# MK81F25615 register map
Vendor: Freescale Semiconductor, Inc.; Series: Kinetis_K; File version: 1.6
CPU: CM4 r0p1, little endian, no MPU, FPU, VTOR, 4 interrupt priority bits
Registers are 32-bit, read-write, reset 0x0 unless marked. A register's access mark holds for its fields unless they carry their own. Offsets are from the block's base; [hi:lo] are bit positions; {n}, {i} and the like mark numbered series; 'fields as' and 'values as' point back to an identical list.

## DAC0 — 12-Bit Digital-to-Analog Converter
Base 0x400CC000; register names take the prefix DAC0_
{0x0+2i} DAT{i}L (i=0..15) 8-bit — DAC Data Low Register
  [7:0] DATA0
{0x1+2i} DAT{i}H (i=0..15) 8-bit — DAC Data High Register
  [3:0] DATA1
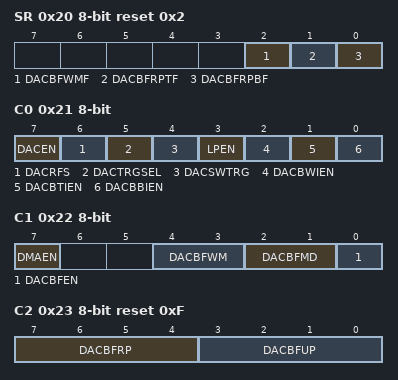
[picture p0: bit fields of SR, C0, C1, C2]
0x20 SR 8-bit reset 0x2 — DAC Status Register
  [2] DACBFWMF — DAC Buffer Watermark Flag
    0=The DAC buffer read pointer has not reached the watermark level; 1=The DAC buffer read pointer has reached the watermark level
  [1] DACBFRPTF — DAC Buffer Read Pointer Top Position Flag
    0=The DAC buffer read pointer is not zero; 1=The DAC buffer read pointer is zero
  [0] DACBFRPBF — DAC Buffer Read Pointer Bottom Position Flag
    0=The DAC buffer read pointer is not equal to C2[DACBFUP]; 1=The DAC buffer read pointer is equal to C2[DACBFUP]
0x21 C0 8-bit — DAC Control Register
  [7] DACEN — DAC Enable
    0=The DAC system is disabled; 1=The DAC system is enabled
  [6] DACRFS — DAC Reference Select
    0=The DAC selects DACREF_1 as the reference voltage; 1=The DAC selects DACREF_2 as the reference voltage
  [5] DACTRGSEL — DAC Trigger Select
    0=The DAC hardware trigger is selected; 1=The DAC software trigger is selected
  [4] DACSWTRG wo — DAC Software Trigger
    0=The DAC soft trigger is not valid; 1=The DAC soft trigger is valid
  [3] LPEN — DAC Low Power Control
    0=High-Power mode; 1=Low-Power mode
  [2] DACBWIEN — DAC Buffer Watermark Interrupt Enable
    0=The DAC buffer watermark interrupt is disabled; 1=The DAC buffer watermark interrupt is enabled
  [1] DACBTIEN — DAC Buffer Read Pointer Top Flag Interrupt Enable
    0=The DAC buffer read pointer top flag interrupt is disabled; 1=The DAC buffer read pointer top flag interrupt is enabled
  [0] DACBBIEN — DAC Buffer Read Pointer Bottom Flag Interrupt Enable
    0=The DAC buffer read pointer bottom flag interrupt is disabled; 1=The DAC buffer read pointer bottom flag interrupt is enabled
0x22 C1 8-bit — DAC Control Register 1
  [7] DMAEN — DMA Enable Select
    0=DMA is disabled; 1=DMA is enabled. When DMA is enabled, the DMA request will be generated by original interrupts. The interrupts will not be presented on this module at the same time.
  [4:3] DACBFWM — DAC Buffer Watermark Select
    0=In normal mode, 1 word . In FIFO mode, 2 or less than 2 data remaining in FIFO will set watermark status bit.; 1=In normal mode, 2 words . In FIFO mode, Max/4 or less than Max/4 data remaining in FIFO will set watermark status bit.; 2=In normal mode, 3 words . In FIFO mode, Max/2 or less than Max/2 data remaining in FIFO will set watermark status bit.; 3=In normal mode, 4 words . In FIFO mode, Max-2 or less than Max-2 data remaining in FIFO will set watermark status bit.
  [2:1] DACBFMD — DAC Buffer Work Mode Select
    0=Normal mode; 1=Swing mode; 2=One-Time Scan mode; 3=FIFO mode
  [0] DACBFEN — DAC Buffer Enable
    0=Buffer read pointer is disabled. The converted data is always the first word of the buffer.; 1=Buffer read pointer is enabled. The converted data is the word that the read pointer points to. It means converted data can be from any word of the buffer.
0x23 C2 8-bit reset 0xF — DAC Control Register 2
  [7:4] DACBFRP — DAC Buffer Read Pointer
  [3:0] DACBFUP — DAC Buffer Upper Limit

## OTFAD
Base 0x400DAC00; register names take the prefix OTFAD_
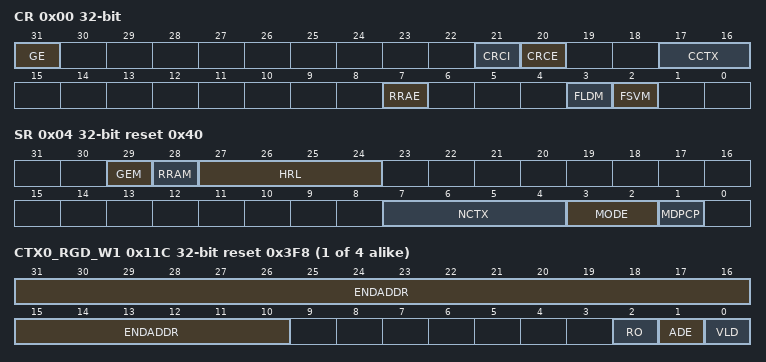
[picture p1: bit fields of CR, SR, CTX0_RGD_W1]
0x00 CR — Control Register
  [31] GE — Global OTFAD Enable
    0=OTFAD has decryption disabled, and bypasses all data fetched by the QuadSPI; 1=OTFAD has decryption enabled, and processes fetched data as defined by the hardware configuration
  [21] CRCI wo — CRC Initialization
    0=CRC data register is unaffected; 1=CRC data register is immediately initialized after a write with this data bit set
  [20] CRCE — CRC Enable
    0=CRC-32 is disabled; 1=CRC-32 for the context defined by CR[CCTRX] is enabled
  [17:16] CCTX — CRC Context
    {v}=Enable CTX{v} CRC check (v=0..3)
  [7] RRAE — Restricted Register Access Enable
    0=Register access is fully enabled. The OTFAD programming model registers can be accessed "normally".; 1=Register access is restricted and only the CR, SR and CRC can be accessed; others are treated as RAZ/WI
  [3] FLDM — Force Logically Disabled Mode
    0=No effect on the operating mode; 1=Force entry into LDM after a write with this data bit set. SR[MODE] signals the operating mode.
  [2] FSVM — Force Security Violation Mode
    0=No effect on the operating mode; 1=Force entry into SVM after a write with this data bit set and the data bit associated with FLDM cleared. SR[MODE] signals the operating mode.
0x04 SR ro reset 0x40 — Status Register
  [29] GEM — Global Enable Mode
    0=OTFAD is disabled, and bypasses all data fetched by the QuadSPI; 1=OTFAD is enabled, and processes data fetched by the QuadSPI as defined by the hardware configuration
  [28] RRAM — Restricted Register Access Mode
    values as CR.RRAE
  [27:24] HRL — Hardware Revision Level
  [7:4] NCTX — Number of Contexts
  [3:2] MODE — Operating Mode
    0=Operating in Normal mode (NRM); 2=Operating in Security Violation Mode (SVM); 3=Operating in Logically Disabled Mode (LDM)
  [1] MDPCP — MDPC Present
0x08 CRC — Cyclic Redundancy Check Register
  [31:0] CRCD — CRC Data.
{0x100+0x40*i} CTX{i}_KEY_W0 (i=0..3) — AES Key Word0
  [31:0] W0KEY — AES Key
{0x104+0x40*i} CTX{i}_KEY_W1 (i=0..3) — AES Key Word1
  [31:0] W1KEY — AES Key
{0x108+0x40*i} CTX{i}_KEY_W2 (i=0..3) — AES Key Word2
  [31:0] W2KEY — AES Key
{0x10C+0x40*i} CTX{i}_KEY_W3 (i=0..3) — AES Key Word3
  [31:0] W3KEY — AES Key
{0x110+0x40*i} CTX{i}_CTR_W0 (i=0..3) — AES Counter Word0
  [31:0] W0CTR — AES Counter
{0x114+0x40*i} CTX{i}_CTR_W1 (i=0..3) — AES Counter Word1
  [31:0] W1CTR — AES Counter
{0x118+0x40*i} CTX{i}_RGD_W0 (i=0..3) — AES Region Descriptor Word0
  [31:10] SRTADDR — Start Address
{0x11C+0x40*i} CTX{i}_RGD_W1 (i=0..3) reset 0x3F8 — AES Region Descriptor Word1
  [31:10] ENDADDR — End Address
  [2] RO — Read-Only
    0=The context registers can be accessed normally (as defined by SR[RRAM]); 1=The context registers are read-only and accesses may be further restricted based on SR[RRAM]
  [1] ADE — Aes Decryption Enable.
    0=Bypass the fetched data; 1=Perform the CTR-AES128 mode decryption on the fetched data
  [0] VLD — Valid
    0=Context is invalid; 1=Context is valid
